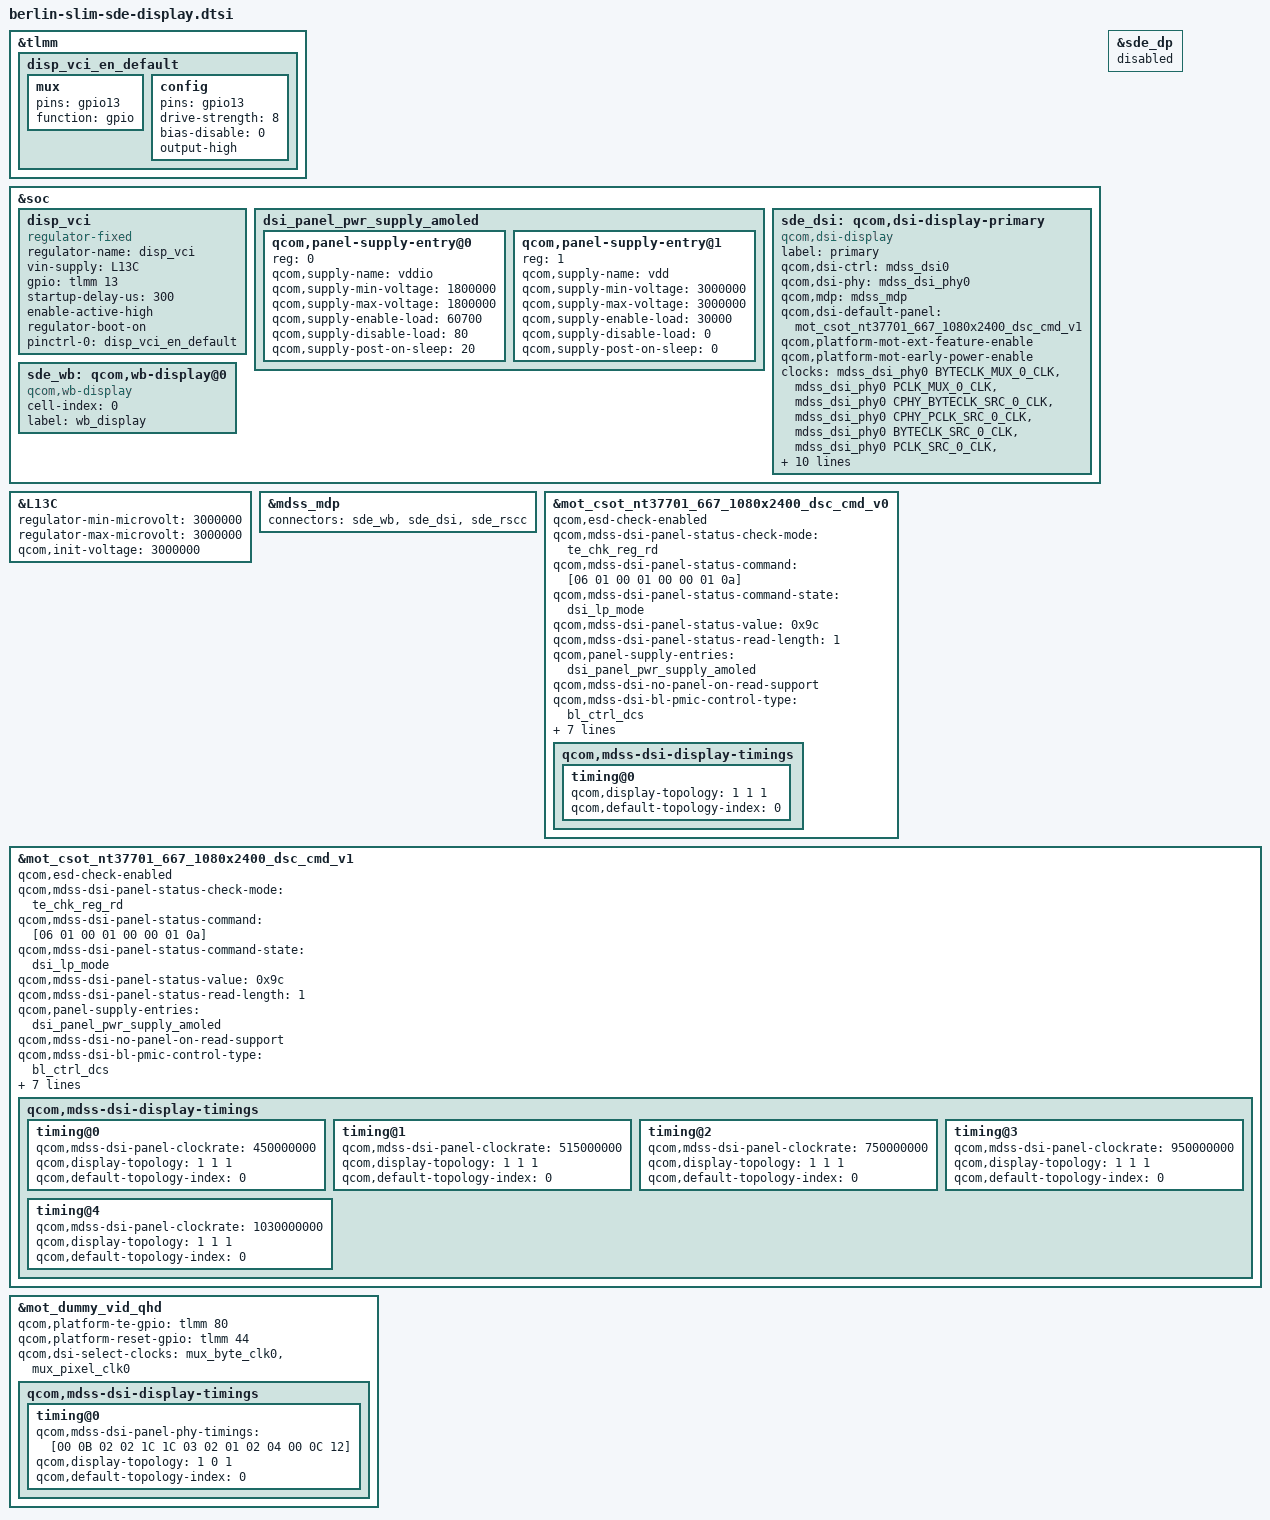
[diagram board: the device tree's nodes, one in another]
#include "dsi-panel-mot-csot-nt37701-667-1080x2400-dsc-cmd-common.dtsi"
#include "dsi-panel-mot-csot-nt37701-667-1080x2400-dsc-cmd-common-v1.dtsi"
#include "dsi-panel-mot-dummy-qhd-video.dtsi"
#include <dt-bindings/clock/mdss-5nm-pll-clk.h>

&tlmm {
	disp_vci_en_default: disp_vci_en_default {
		mux {
			pins = "gpio13";
			function = "gpio";
		};

		config {
			pins = "gpio13";
			drive-strength = <8>;
			bias-disable = <0>;
			output-high;
		};
	};
};

&soc {
	disp_vci: disp_vci {
		compatible = "regulator-fixed";
		regulator-name = "disp_vci";
		vin-supply = <&L13C>;
		gpio = <&tlmm 13 0>;
		startup-delay-us = <300>;
		enable-active-high;
		regulator-boot-on;
		pinctrl-names = "default";
		pinctrl-0 = <&disp_vci_en_default>;
	};

	dsi_panel_pwr_supply_amoled: dsi_panel_pwr_supply_amoled {
		#address-cells = <1>;
		#size-cells = <0>;

		qcom,panel-supply-entry@0 {
			reg = <0>;
			qcom,supply-name = "vddio";
			qcom,supply-min-voltage = <1800000>;
			qcom,supply-max-voltage = <1800000>;
			qcom,supply-enable-load = <60700>;
			qcom,supply-disable-load = <80>;
			qcom,supply-post-on-sleep = <20>;
		};

		qcom,panel-supply-entry@1 {
			reg = <1>;
			qcom,supply-name = "vdd";
			qcom,supply-min-voltage = <3000000>;
			qcom,supply-max-voltage = <3000000>;
			qcom,supply-enable-load = <30000>;
			qcom,supply-disable-load = <0>;
			qcom,supply-post-on-sleep = <0>;
		};
	};

	sde_dsi: qcom,dsi-display-primary {
		compatible = "qcom,dsi-display";
		label = "primary";

		qcom,dsi-ctrl = <&mdss_dsi0>;
		qcom,dsi-phy = <&mdss_dsi_phy0>;

		qcom,mdp = <&mdss_mdp>;
		qcom,dsi-default-panel = <&mot_csot_nt37701_667_1080x2400_dsc_cmd_v1>;
	};
};

&soc {
	sde_wb: qcom,wb-display@0 {
		compatible = "qcom,wb-display";
		cell-index = <0>;
		label = "wb_display";
	};
};

&sde_dp {
	status = "disabled";
};

&sde_dsi {
	qcom,platform-mot-ext-feature-enable;
	qcom,platform-mot-early-power-enable;
};

&sde_dsi {
	clocks = <&mdss_dsi_phy0 BYTECLK_MUX_0_CLK>,
			 <&mdss_dsi_phy0 PCLK_MUX_0_CLK>,
			 <&mdss_dsi_phy0 CPHY_BYTECLK_SRC_0_CLK>,
			 <&mdss_dsi_phy0 CPHY_PCLK_SRC_0_CLK>,
			 <&mdss_dsi_phy0 BYTECLK_SRC_0_CLK>,
			 <&mdss_dsi_phy0 PCLK_SRC_0_CLK>,
			 <&mdss_dsi_phy0 SHADOW_BYTECLK_SRC_0_CLK>,
			 <&mdss_dsi_phy0 SHADOW_PCLK_SRC_0_CLK>,
			 <&mdss_dsi_phy0 SHADOW_CPHY_BYTECLK_SRC_0_CLK>,
			 <&mdss_dsi_phy0 SHADOW_CPHY_PCLK_SRC_0_CLK>;
	clock-names = "mux_byte_clk0", "mux_pixel_clk0",
			"cphy_byte_clk0", "cphy_pixel_clk0",
			"src_byte_clk0", "src_pixel_clk0",
			"shadow_byte_clk0", "shadow_pixel_clk0",
			"shadow_cphybyte_clk0", "shadow_cphypixel_clk0";

	pinctrl-names = "panel_active", "panel_suspend";
	pinctrl-0 = <&sde_dsi_active &sde_te_active>;
	pinctrl-1 = <&sde_dsi_suspend &sde_te_suspend>;

	qcom,platform-te-gpio = <&tlmm 80 0>;
	qcom,panel-te-source = <0>;

	vddio-supply = <&L12C>;
	vdd-supply = <&disp_vci>;

};

&L13C {
	regulator-min-microvolt = <3000000>;
	regulator-max-microvolt = <3000000>;
	qcom,init-voltage = <3000000>;
};

&mdss_mdp {
	connectors = <&sde_wb &sde_dsi &sde_rscc>;
};


&mot_csot_nt37701_667_1080x2400_dsc_cmd_v0 {
	qcom,esd-check-enabled;
	qcom,mdss-dsi-panel-status-check-mode = "te_chk_reg_rd";
	qcom,mdss-dsi-panel-status-command = [06 01 00 01 00 00 01 0a];
	qcom,mdss-dsi-panel-status-command-state = "dsi_lp_mode";
	qcom,mdss-dsi-panel-status-value = <0x9c>;
	qcom,mdss-dsi-panel-status-read-length = <1>;

	qcom,panel-supply-entries = <&dsi_panel_pwr_supply_amoled>;
	qcom,mdss-dsi-no-panel-on-read-support;
	qcom,mdss-dsi-bl-pmic-control-type = "bl_ctrl_dcs";
	qcom,mdss-dsi-bl-min-level = <1>;
	qcom,mdss-dsi-bl-max-level = <2047>;
	qcom,mdss-dsi-bl-default-level = <1024>;
	qcom,mdss-brightness-max-level = <2047>;
	qcom,platform-reset-gpio = <&tlmm 44 0>;

	qcom,dsi-select-clocks = "mux_byte_clk0", "mux_pixel_clk0";
	qcom,mdss-dsi-display-timings {
		timing@0 {
			//qcom,mdss-dsi-panel-clockrate = <938000000>;
			qcom,display-topology = <1 1 1>;
			qcom,default-topology-index = <0>;
		};
	};
};

&mot_csot_nt37701_667_1080x2400_dsc_cmd_v1 {
	qcom,esd-check-enabled;
	qcom,mdss-dsi-panel-status-check-mode = "te_chk_reg_rd";
	qcom,mdss-dsi-panel-status-command = [06 01 00 01 00 00 01 0a];
	qcom,mdss-dsi-panel-status-command-state = "dsi_lp_mode";
	qcom,mdss-dsi-panel-status-value = <0x9c>;
	qcom,mdss-dsi-panel-status-read-length = <1>;

	qcom,panel-supply-entries = <&dsi_panel_pwr_supply_amoled>;
	qcom,mdss-dsi-no-panel-on-read-support;
	qcom,mdss-dsi-bl-pmic-control-type = "bl_ctrl_dcs";
	qcom,mdss-dsi-bl-min-level = <1>;
	qcom,mdss-dsi-bl-max-level = <2047>;
	qcom,mdss-dsi-bl-default-level = <1024>;
	qcom,mdss-brightness-max-level = <2047>;
	qcom,platform-reset-gpio = <&tlmm 44 0>;

	qcom,dsi-select-clocks = "mux_byte_clk0", "mux_pixel_clk0";

	qcom,mdss-dsi-display-timings {
		timing@0 {
			qcom,mdss-dsi-panel-clockrate = <450000000>;
			qcom,display-topology = <1 1 1>;
			qcom,default-topology-index = <0>;
			//qcom,mdss-dsi-panel-phy-timings = [00 0D 03 03 10 1D 03
			//				03 02 02 04 00 0C 08];
		};
		timing@1 {
			qcom,mdss-dsi-panel-clockrate = <515000000>;
			qcom,display-topology = <1 1 1>;
			qcom,default-topology-index = <0>;
			//qcom,mdss-dsi-panel-phy-timings = [00 10 03 03 11 1E 04
			//				04 03 02 04 00 0E 08];
		};
		timing@2 {
			qcom,mdss-dsi-panel-clockrate = <750000000>;
			qcom,display-topology = <1 1 1>;
			qcom,default-topology-index = <0>;
			//qcom,mdss-dsi-panel-phy-timings = [00 15 05 05 14 1F 05
			//				05 06 02 04 00 13 0A];
		};
		timing@3 {
			qcom,mdss-dsi-panel-clockrate = <950000000>;
			qcom,display-topology = <1 1 1>;
			qcom,default-topology-index = <0>;
			//qcom,mdss-dsi-panel-phy-timings = [00 1A 07 06 16 15 07
			//				07 07 02 04 00 17 0B];
		};
		timing@4 {
			qcom,mdss-dsi-panel-clockrate = <1030000000>;
			qcom,display-topology = <1 1 1>;
			qcom,default-topology-index = <0>;
			//qcom,mdss-dsi-panel-phy-timings = [00 1F 08 07 18 16 08
			//				08 08 02 04 00 1A 0C];
		};
	};
};

&mot_dummy_vid_qhd {
	qcom,platform-te-gpio = <&tlmm 80 0>;
	qcom,platform-reset-gpio = <&tlmm 44 0>;

	qcom,dsi-select-clocks = "mux_byte_clk0", "mux_pixel_clk0";
	qcom,mdss-dsi-display-timings {
		timing@0 {
			qcom,mdss-dsi-panel-phy-timings = [00 0B 02 02 1C 1C 03
							02 01 02 04 00 0C 12];
			qcom,display-topology = <1 0 1>;
			qcom,default-topology-index = <0>;
		};
	};
};

